VERSION ""

NS_ :

BS_:

BU_: TelemetryTest

BO_ 2046 Sig_Wave: 8 TelemetryTest
 SG_ Sine : 0|32@1+ (1,0) [-1|1] "" Vector__XXX
 SG_ Cosine : 32|32@1+ (1,0) [-1|1] "" Vector__XXX

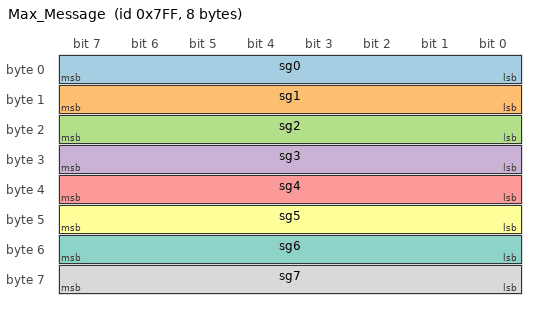
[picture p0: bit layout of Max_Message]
BO_ 2047 Max_Message: 8 TelemetryTest
 SG_ sg0 : 0|8@1+ (1,0) [0|1] "unit" Vector__XXX
 SG_ sg1 : 8|8@1+ (1,0) [0|1] "unit" Vector__XXX
 SG_ sg2 : 16|8@1+ (1,0) [0|1] "unit" Vector__XXX
 SG_ sg3 : 24|8@1+ (1,0) [0|1] "unit" Vector__XXX
 SG_ sg4 : 32|8@1+ (1,0) [0|1] "unit" Vector__XXX
 SG_ sg5 : 40|8@1+ (1,0) [0|1] "unit" Vector__XXX
 SG_ sg6 : 48|8@1+ (1,0) [0|1] "unit" Vector__XXX
 SG_ sg7 : 56|8@1+ (1,0) [0|1] "unit" Vector__XXX

SIG_VALTYPE_ 2046 Sine : 1;
SIG_VALTYPE_ 2046 Cosine : 1;

BA_DEF_  "DBName" STRING ;
BA_DEF_ BO_  "VFrameFormat" ENUM  "StandardCAN","ExtendedCAN","reserved","J1939PG","reserved","reserved","reserved","reserved","reserved","reserved","reserved","reserved","reserved","reserved","StandardCAN_FD","ExtendedCAN_FD";
BA_DEF_  "BusType" STRING ;
BA_DEF_DEF_  "DBName" "";
BA_DEF_DEF_  "VFrameFormat" "StandardCAN";
BA_DEF_DEF_  "BusType" "";
BA_ "BusType" "CAN";
BA_ "DBName" "TelemetryTest";
